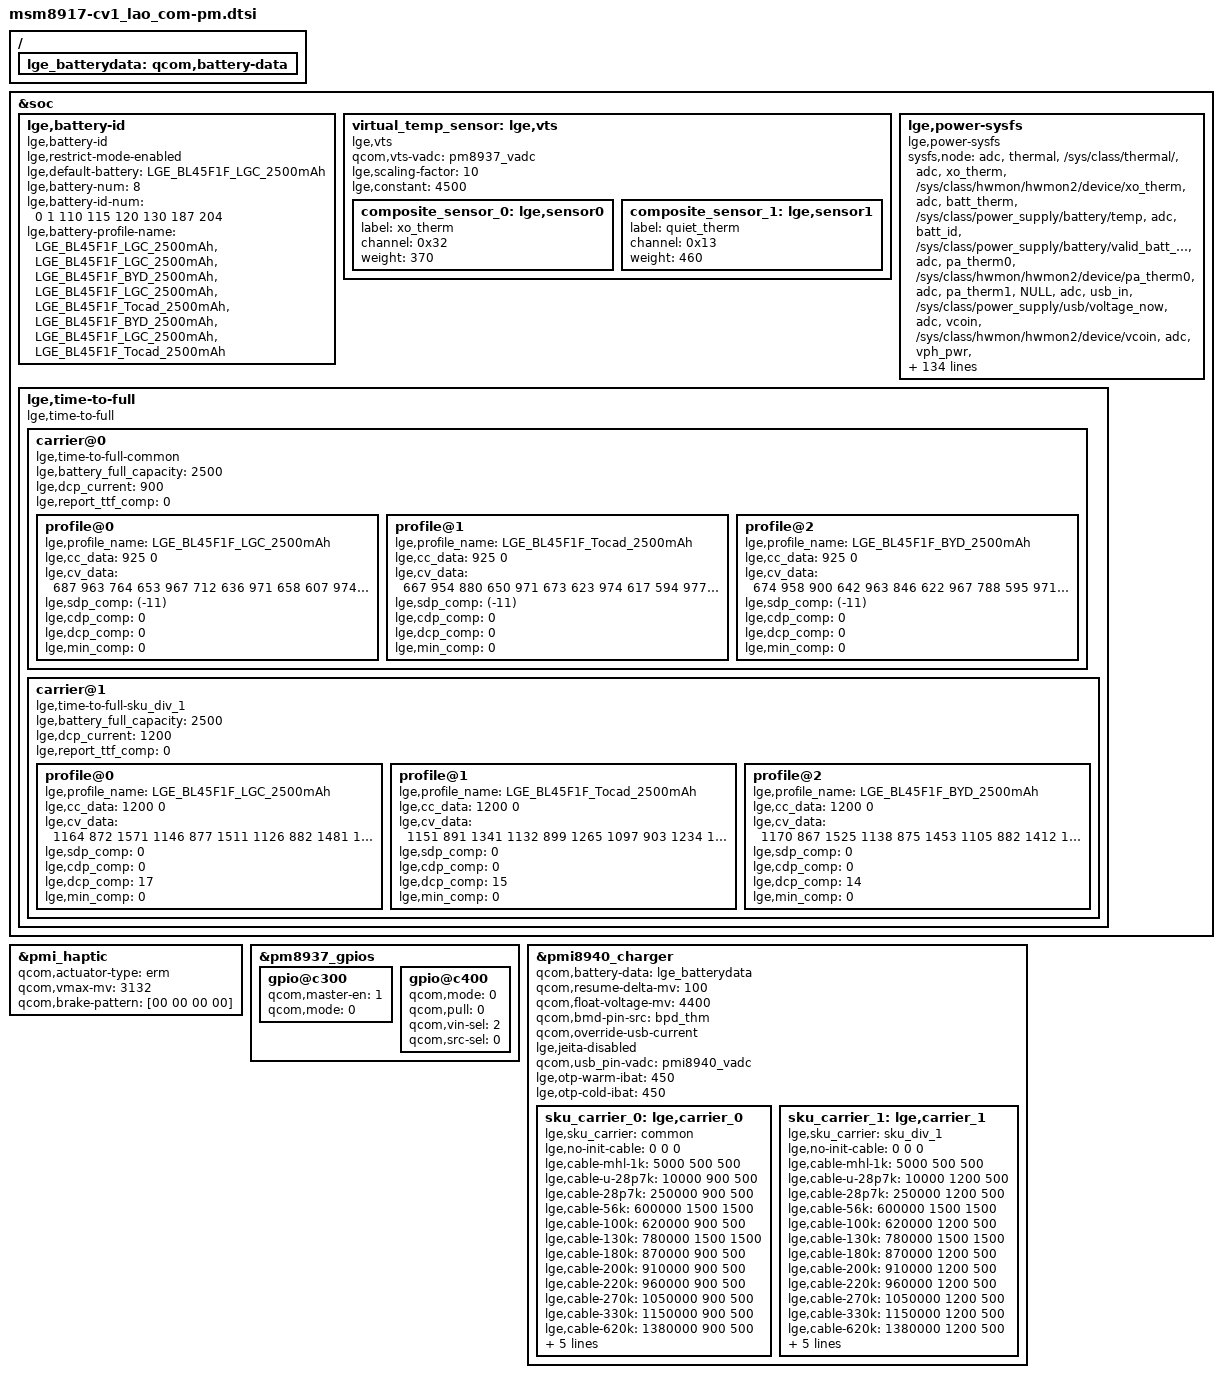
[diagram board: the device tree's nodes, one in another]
/*
 * Copyright (c) 2016, The Linux Foundation. All rights reserved.
 *
 * This program is free software; you can redistribute it and/or modify
 * it under the terms of the GNU General Public License version 2 and
 * only version 2 as published by the Free Software Foundation.
 *
 * This program is distributed in the hope that it will be useful,
 * but WITHOUT ANY WARRANTY; without even the implied warranty of
 * MERCHANTABILITY or FITNESS FOR A PARTICULAR PURPOSE.  See the
 * GNU General Public License for more details.
 */

/{
    lge_batterydata: qcom,battery-data {
         #include "../battery_profile/LGE_BL45F1F_LGC_2500mAh.dtsi"
         #include "../battery_profile/LGE_BL45F1F_Tocad_2500mAh.dtsi"
         #include "../battery_profile/LGE_BL45F1F_BYD_2500mAh.dtsi"
    };
};

&soc {
	lge,battery-id{
		compatible = "lge,battery-id";
		lge,restrict-mode-enabled;
		/*default battery profile*/
		lge,default-battery = "LGE_BL45F1F_LGC_2500mAh";
		/*Total number of combined of battery cell and battery id */
		lge,battery-num = <8>;
		/* battery id and battery profile match numbers */
		lge,battery-id-num = <0 1 110 115 120 130 187 204>;
		/* battery profile */
		lge,battery-profile-name = "LGE_BL45F1F_LGC_2500mAh",
						"LGE_BL45F1F_LGC_2500mAh",
						"LGE_BL45F1F_BYD_2500mAh",
						"LGE_BL45F1F_LGC_2500mAh",
						"LGE_BL45F1F_Tocad_2500mAh",
						"LGE_BL45F1F_BYD_2500mAh",
						"LGE_BL45F1F_LGC_2500mAh",
						"LGE_BL45F1F_Tocad_2500mAh";
	};

	/* vts = (0.37*xo_therm) + (0.46*quiet_therm) + 4.5 */
	virtual_temp_sensor: lge,vts {
		compatible = "lge,vts";
		qcom,vts-vadc = <&pm8937_vadc>;
		lge,scaling-factor= <10>;
		lge,constant = <4500>;
		composite_sensor_0: lge,sensor0 {
			label = "xo_therm";
			channel = <0x32>;
			weight = <370>;
		};
		composite_sensor_1: lge,sensor1 {
			label = "quiet_therm";
			channel = <0x13>;
			weight = <460>;
		};
	};

	lge,power-sysfs {
		compatible = "lge,power-sysfs";

		sysfs,node =
			/* group , user_node,  kernel node */
			/* ADC/MPP */
			"adc", "thermal", "/sys/class/thermal/",
			"adc", "xo_therm", "/sys/class/hwmon/hwmon2/device/xo_therm",
			"adc", "batt_therm", "/sys/class/power_supply/battery/temp",
			"adc", "batt_id", "/sys/class/power_supply/battery/valid_batt_id",
			"adc", "pa_therm0", "/sys/class/hwmon/hwmon2/device/pa_therm0",
			"adc", "pa_therm1", "NULL", /* Not use */
			"adc", "usb_in", "/sys/class/power_supply/usb/voltage_now",
			"adc", "vcoin", "/sys/class/hwmon/hwmon2/device/vcoin",
			"adc", "vph_pwr", "/sys/class/hwmon/hwmon2/device/vph_pwr",
			"adc", "vts", "/sys/class/thermal/thermal_zone18/temp",
			"adc", "usb_id", "/sys/class/hwmon/hwmon7/device/mpp1_usb_id",
			"adc", "quiet_therm", "/sys/class/hwmon/hwmon2/device/quiet_therm",
			/* Battery */
			"battery", "capacity", "/sys/class/power_supply/battery/capacity",
			"battery", "health", "/sys/class/power_supply/battery/health",
			"battery", "present", "/sys/class/power_supply/battery/present",
			"battery", "pseudo_batt", "/sys/class/power_supply/battery/pseudo_batt",
			"battery", "status", "/sys/class/power_supply/battery/status",
			"battery", "temp", "/sys/class/power_supply/battery/temp",
			"battery", "valid_batt_id", "/sys/class/power_supply/battery/valid_batt_id",
			"battery", "voltage_now", "/sys/class/power_supply/battery/voltage_now",
			"battery", "charge_full", "/sys/class/power_supply/bms/charge_full",
			"battery", "charge_now_raw", "/sys/class/power_supply/bms/charge_now_raw",
			"battery", "cycle", "/sys/class/power_supply/bms/battery_cycle",
			"battery", "battery_type", "/sys/class/power_supply/bms/battery_type",
			"battery", "time_to_full_now", "/sys/class/power_supply/battery/time_to_full_now",
                        "battery", "vzw_chg", "/sys/class/power_supply/battery/vzw_chg",
			/* Charger */
			"charger", "ac_online", "NULL",
			"charger", "usb_online", "/sys/class/power_supply/usb/online",
			"charger", "present", "/sys/class/power_supply/usb/present",
			"charger", "wlc_online", "NULL",
			"charger", "type", "/sys/class/power_supply/usb/real_type",
			"charger", "time_out", "/sys/class/power_supply/battery/safety_timer_enabled",
			"charger", "charging_enabled", "/sys/class/power_supply/battery/charging_enabled",
			"charger", "ibat_current", "/sys/class/power_supply/battery/current_now",
			"charger", "ichg_current", "/sys/class/power_supply/usb/current_max",
			"charger", "iusb_control", "NULL",
			"charger", "thermal_mitigation", "/sys/module/qpnp_linear_charger/parameters/qpnp_thermal_mitigation", /* Fix */
			"charger", "wlc_thermal_mitigation", "NULL",
			"charger", "usb_parallel_chg_status", "NULL",
			"charger", "usb_parallel_charging_enabled", "NULL",
			"charger", "restricted_charging", "/sys/module/qpnp_smbcharger/parameters/restricted_charging",
			"charger", "fastchg",             "/sys/class/power_supply/usb/fastchg",
			"charger", "chgstep",             "/sys/class/power_supply/battery/device/chgstep",
			"charger", "incompatible",        "/sys/class/power_supply/usb/incompatible_chg",
			"charger", "ext_pwr",             "/sys/class/power_supply/battery/ext_pwr",
			/* LCD Backlight */
			"lcd", "brightness", "/sys/class/leds/lcd-backlight/brightness",
			"lcd", "max_brightness", "/sys/class/leds/lcd-backlight/max_brightness",
			/* KEY LED */
			"key_led", "red_brightness", "/sys/class/leds/red/brightness", /* Fix */
			"key_led", "green_brightness", "/sys/class/leds/green/brightness", /* Fix */
			"key_led", "blue_brightness", "/sys/class/leds/blue/brightness", /* Fix */
			/* CPU */
			"cpu", "cpu_idle_modes", "NULL",
			/* GPU */
			"gpu", "busy", "/sys/class/kgsl/kgsl-3d0/gpubusy",
			"gpu", "gpuclk", "/sys/class/kgsl/kgsl-3d0/gpuclk",
			/* PLATFORM */
			"platform", "speed_bin", "NULL",
			"platform", "pvs_bin", "NULL",
			"platform", "power_state", "/sys/power/autosleep",
			"platform", "poweron_alarm", "/sys/module/qpnp_rtc/parameters/poweron_alarm",
			"platform", "pcb_rev", "/sys/class/hwmon/hwmon2/device/mpp2_pcb_rev",
			"platform", "smpl_boot", "/sys/module/lge_smpl_count/parameters/smpl_boot",
			/* testmode */
			"testmode", "temp", "/sys/class/power_supply/battery/temp",
			"testmode", "voltage_now", "/sys/class/power_supply/battery/voltage_now",
			"testmode", "usb_id", "/sys/class/hwmon/hwmon7/device/mpp1_usb_id",
			"testmode", "fuelval", "/sys/class/power_supply/battery/capacity",
			"testmode", "xo_therm", "/sys/class/hwmon/hwmon2/device/xo_therm",
			"testmode", "batt_id", "/sys/class/power_supply/battery/valid_batt_id",
			"testmode", "charge", "/sys/class/power_supply/battery/device/at_charge",
			"testmode", "chcomp", "/sys/class/power_supply/battery/device/at_chcomp",
			"testmode", "usbin", "/sys/class/hwmon/hwmon7/device/usbin",
			"testmode", "pa_therm0", "/sys/class/hwmon/hwmon2/device/pa_therm0",
			"testmode", "vcoin", "/sys/class/hwmon/hwmon2/device/vcoin",
			"testmode", "vph_pwr", "/sys/class/hwmon/hwmon2/device/vph_pwr",
			"testmode", "current_now", "/sys/class/power_supply/battery/current_now",
			"testmode", "current_max", "/sys/class/power_supply/usb/current_max",
			"testmode", "pcb_rev", "/sys/class/hwmon/hwmon2/device/mpp2_pcb_rev",
			"testmode", "chgmodeoff", "/sys/class/power_supply/battery/charging_enabled",
			"testmode", "fuelrst", "/sys/class/power_supply/battery/present",
			"testmode", "rtc_time", "/dev/rtc0",
			"testmode", "pmrst", "/sys/class/power_supply/battery/device/at_pmrst",
			"testmode", "battexit", "/sys/class/power_supply/battery/present",
			/* ps feature */
			"psfeature", "vfps_ratio", "/sys/class/graphics/fb0/mdp/vfps_ratio",
			"psfeature", "vfps", "/sys/class/graphics/fb0/mdp/vfps",
			"psfeature", "vfps_fcnt", "/sys/class/graphics/fb0/mdp/vfps_fcnt",
			"psfeature", "triton_policy", "NULL",
			"psfeature", "cancun_is_cm", "NULL";
	};

	/* time to full */
	lge,time-to-full {
		compatible = "lge,time-to-full";

		carrier@0 {
			compatible = "lge,time-to-full-common";
			lge,battery_full_capacity = <2500>;
			lge,dcp_current = <900>;
			lge,report_ttf_comp = <0>;
			profile@0 {
				lge,profile_name = "LGE_BL45F1F_LGC_2500mAh";
					/* current  soc */
				lge,cc_data = < 925 0 >;
					/* current  soc    time */
				lge,cv_data = < 687 963 764
						653 967 712
						636 971 658
						607 974 601
						587 977 542
						558 980 482
						540 983 420
						511 986 355
						490 989 289
						469 993 220
						452 996 150
						428 999 76
						411 1000 0 >;
				lge,sdp_comp = <(-11)>;
				lge,cdp_comp = <0>;
				lge,dcp_comp = <0>;
				lge,min_comp = <0>;
			};
			profile@1 {
				lge,profile_name = "LGE_BL45F1F_Tocad_2500mAh";
					/* current  soc */
				lge,cc_data = < 925 0 >;
					/* current  soc    time */
				lge,cv_data = < 667 954 880
						650 971 673
						623 974 617
						594 977 556
						568 980 495
						546 983 429
						520 986 363
						502 989 295
						472 993 225
						453 996 152
						425 999 77
						412 1000 0 >;
				lge,sdp_comp = <(-11)>;
				lge,cdp_comp = <0>;
				lge,dcp_comp = <0>;
				lge,min_comp = <0>;
			};
			profile@2 {
				lge,profile_name = "LGE_BL45F1F_BYD_2500mAh";
					/* current  soc */
				lge,cc_data = < 925 0 >;
					/* current  soc    time */
				lge,cv_data = < 674 958 900
						642 963 846
						622 967 788
						595 971 728
						574 974 667
						545 977 603
						531 980 537
						500 983 468
						482 986 398
						455 989 325
						438 993 247
						414 996 168
						399 999 86
						374 1000 0 >;
				lge,sdp_comp = <(-11)>;
				lge,cdp_comp = <0>;
				lge,dcp_comp = <0>;
				lge,min_comp = <0>;
			};
		};
		carrier@1 {
			compatible = "lge,time-to-full-sku_div_1";
			lge,battery_full_capacity = <2500>;
			lge,dcp_current = <1200>;
			lge,report_ttf_comp = <0>;
			profile@0 {
				lge,profile_name = "LGE_BL45F1F_LGC_2500mAh";
					    /* current  soc */
				lge,cc_data = < 1200	0>;
					    /* current  soc    time */
				lge,cv_data = < 1164 872 1571
						1146 877 1511
						1126 882 1481
						1101 886 1451
						1074 890 1420
						1051 895 1387
						1027 899 1355
						1007 903 1321
						978 907 1287
						956 912 1252
						931 916 1215
						905 920 1184
						883 924 1141
						861 929 1103
						836 933 1063
						811 937 1021
						788 941 979
						761 946 935
						741 950 891
						716 954 844
						689 958 797
						667 963 745
						642 967 697
						620 971 644
						598 974 587
						573 977 534
						549 980 476
						529 983 415
						503 986 352
						484 989 286
						461 993 219
						442 996 149
						417 999 76
						399 1000 0>;
				lge,sdp_comp = <0>;
				lge,cdp_comp = <0>;
				lge,dcp_comp = <17>;
				lge,min_comp = <0>;
			};
			profile@1 {
				lge,profile_name = "LGE_BL45F1F_Tocad_2500mAh";
					    /* current  soc */
				lge,cc_data = < 1200	0>;
					    /* current  soc    time */
				lge,cv_data = < 1151 891 1341
						1132 899 1265
						1097 903 1234
						1069 907 1202
						1040 912 1168
						982 920 1099
						929 929 1027
						904 933 990
						806 939 932
						754 950 828
						735 958 740
						709 963 694
						681 967 646
						653 971 596
						627 974 545
						603 977 493
						577 980 439
						554 983 383
						528 986 324
						503 990 256
						481 993 204
						460 996 138
						437 999 71
						415 1000 0>;
				lge,sdp_comp = <0>;
				lge,cdp_comp = <0>;
				lge,dcp_comp = <15>;
				lge,min_comp = <0>;
			};
			profile@2 {
				lge,profile_name = "LGE_BL45F1F_BYD_2500mAh";
					    /* current  soc */
				lge,cc_data = < 1200	0>;
					    /* current  soc    time */
				lge,cv_data = < 1170 867 1525
						1138 875 1453
						1105 882 1412
						1082 886 1384
						1065 890 1347
						1043 895 1317
						1019 899 1287
						993 903 1256
						955 907 1237
						936 912 1199
						913 916 1165
						890 920 1131
						866 924 1095
						841 929 1059
						820 933 1021
						794 937 986
						769 941 941
						745 946 899
						720 950 856
						659 956 789
						650 963 717
						625 967 669
						605 971 615
						579 974 568
						555 977 515
						534 980 459
						514 983 402
						490 986 342
						469 989 278
						447 993 213
						426 996 146
						404 999 75
						383 1000 0>;
				lge,sdp_comp = <0>;
				lge,cdp_comp = <0>;
				lge,dcp_comp = <14>;
				lge,min_comp = <0>;
			};
		};
	};
};

&pmi_haptic{
	status = "okay";
	qcom,actuator-type = "erm";
	qcom,vmax-mv = <3132>;
	qcom,brake-pattern = [00 00 00 00];
};

&pm8937_gpios {
	gpio@c300 {
		qcom,master-en = <1>;
		qcom,mode = <0>;
		status = "okay";
	};

	gpio@c400 {
		qcom,mode = <0>;
		qcom,pull = <0>;
		qcom,vin-sel = <2>;
		qcom,src-sel = <0>;
		status = "okay";
	};
};

&pmi8940_charger {
	qcom,battery-data = <&lge_batterydata>;
	qcom,resume-delta-mv = <100>;
	qcom,float-voltage-mv = <4400>;
	qcom,bmd-pin-src = "bpd_thm";
	qcom,override-usb-current;
	lge,jeita-disabled;

	qcom,usb_pin-vadc = <&pmi8940_vadc>;

	lge,otp-warm-ibat = <450>;
	lge,otp-cold-ibat = <450>;

	sku_carrier_0:	lge,carrier_0 {
		lge,sku_carrier = "common";

		/* ref resistance 200K */
		lge,no-init-cable = <0 0 0>;
		lge,cable-mhl-1k = <5000 500 500>;
		lge,cable-u-28p7k = <10000 900 500>;
		lge,cable-28p7k = <250000 900 500>;
		lge,cable-56k = <600000 1500 1500>;
		lge,cable-100k = <620000 900 500>;
		lge,cable-130k = <780000 1500 1500>;
		lge,cable-180k = <870000 900 500>;
		lge,cable-200k = <910000 900 500>;
		lge,cable-220k = <960000 900 500>;
		lge,cable-270k = <1050000 900 500>;
		lge,cable-330k = <1150000 900 500>;
		lge,cable-620k = <1380000 900 500>;
		lge,cable-910k = <1630000 1500 1500>;
		lge,cable-none = <1900000 900  500>;

		lge,usb-max-current-ma = <900>;
		lge,fastchg-current-ma = <900>;
		lge,hvdcp-not-supported;
	};
	sku_carrier_1: lge,carrier_1 {
		lge,sku_carrier = "sku_div_1";

		/* ref resistance 200K */
		lge,no-init-cable = <0 0 0>;
		lge,cable-mhl-1k = <5000 500 500>;
		lge,cable-u-28p7k = <10000 1200 500>;
		lge,cable-28p7k = <250000 1200 500>;
		lge,cable-56k = <600000 1500 1500>;
		lge,cable-100k = <620000 1200 500>;
		lge,cable-130k = <780000 1500 1500>;
		lge,cable-180k = <870000 1200 500>;
		lge,cable-200k = <910000 1200 500>;
		lge,cable-220k = <960000 1200 500>;
		lge,cable-270k = <1050000 1200 500>;
		lge,cable-330k = <1150000 1200 500>;
		lge,cable-620k = <1380000 1200 500>;
		lge,cable-910k = <1630000 1500 1500>;
		lge,cable-none = <1900000 1200  500>;

		lge,usb-max-current-ma = <1200>;
		lge,fastchg-current-ma = <1200>;
		lge,hvdcp-not-supported;
	};

};
